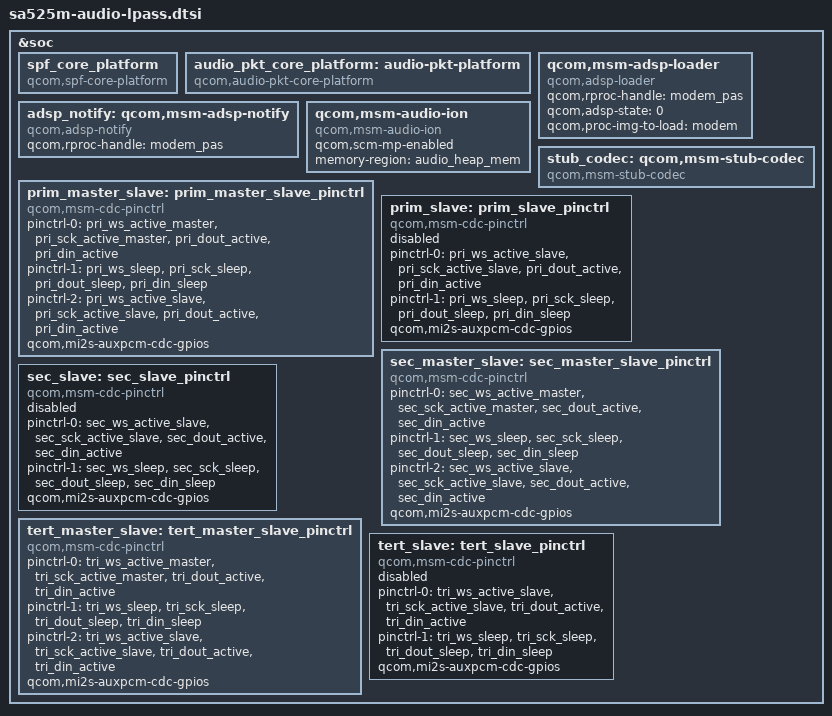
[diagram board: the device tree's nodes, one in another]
&soc {
	spf_core_platform: spf_core_platform {
		compatible = "qcom,spf-core-platform";
	};

	audio_pkt_core_platform: audio-pkt-platform {
		compatible = "qcom,audio-pkt-core-platform";
	};

	qcom,msm-adsp-loader {
		compatible = "qcom,adsp-loader";
		qcom,rproc-handle = <&modem_pas>;
		qcom,adsp-state = <0>;
		qcom,proc-img-to-load = "modem";
	};

	adsp_notify: qcom,msm-adsp-notify {
		status = "ok";
		compatible = "qcom,adsp-notify";
		qcom,rproc-handle = <&modem_pas>;
	};

	qcom,msm-audio-ion {
		compatible = "qcom,msm-audio-ion";
		qcom,scm-mp-enabled;
		memory-region = <&audio_heap_mem>;
	};

	stub_codec: qcom,msm-stub-codec {
		compatible = "qcom,msm-stub-codec";
	};

	prim_master_slave: prim_master_slave_pinctrl {
		compatible = "qcom,msm-cdc-pinctrl";
		pinctrl-names = "aud_active", "aud_sleep", "aud_alt_active";
		pinctrl-0 = <&pri_ws_active_master
				&pri_sck_active_master
				&pri_dout_active
				&pri_din_active>;
		pinctrl-1 = <&pri_ws_sleep
				&pri_sck_sleep
				&pri_dout_sleep
				&pri_din_sleep>;
		pinctrl-2 = <&pri_ws_active_slave
				&pri_sck_active_slave
				&pri_dout_active
				&pri_din_active>;
		qcom,mi2s-auxpcm-cdc-gpios;
	};

	prim_slave: prim_slave_pinctrl {
		status = "disabled";
		compatible = "qcom,msm-cdc-pinctrl";
		pinctrl-names = "aud_active", "aud_sleep";
		pinctrl-0 = <&pri_ws_active_slave
				&pri_sck_active_slave
				&pri_dout_active
				&pri_din_active>;
		pinctrl-1 = <&pri_ws_sleep
				&pri_sck_sleep
				&pri_dout_sleep
				&pri_din_sleep>;
		qcom,mi2s-auxpcm-cdc-gpios;
	};

	sec_master_slave: sec_master_slave_pinctrl {
		compatible = "qcom,msm-cdc-pinctrl";
		pinctrl-names = "aud_active", "aud_sleep", "aud_alt_active";
		pinctrl-0 = <&sec_ws_active_master
				&sec_sck_active_master
				&sec_dout_active
				&sec_din_active>;
		pinctrl-1 = <&sec_ws_sleep
				&sec_sck_sleep
				&sec_dout_sleep
				&sec_din_sleep>;
		pinctrl-2 = <&sec_ws_active_slave
				&sec_sck_active_slave
				&sec_dout_active
				&sec_din_active>;
		qcom,mi2s-auxpcm-cdc-gpios;
	};

	sec_slave: sec_slave_pinctrl {
		status = "disabled";
		compatible = "qcom,msm-cdc-pinctrl";
		pinctrl-names = "aud_active", "aud_sleep";
		pinctrl-0 = <&sec_ws_active_slave
				&sec_sck_active_slave
				&sec_dout_active
				&sec_din_active>;
		pinctrl-1 = <&sec_ws_sleep
				&sec_sck_sleep
				&sec_dout_sleep
				&sec_din_sleep>;
		qcom,mi2s-auxpcm-cdc-gpios;
	};

	tert_master_slave: tert_master_slave_pinctrl {
		compatible = "qcom,msm-cdc-pinctrl";
		pinctrl-names = "aud_active", "aud_sleep", "aud_alt_active";
		pinctrl-0 = <&tri_ws_active_master
				&tri_sck_active_master
				&tri_dout_active
				&tri_din_active>;
		pinctrl-1 = <&tri_ws_sleep
				&tri_sck_sleep
				&tri_dout_sleep
				&tri_din_sleep>;
		pinctrl-2 = <&tri_ws_active_slave
				&tri_sck_active_slave
				&tri_dout_active
				&tri_din_active>;
		qcom,mi2s-auxpcm-cdc-gpios;
	};

	tert_slave: tert_slave_pinctrl {
		status = "disabled";
		compatible = "qcom,msm-cdc-pinctrl";
		pinctrl-names = "aud_active", "aud_sleep";
		pinctrl-0 = <&tri_ws_active_slave
				&tri_sck_active_slave
				&tri_dout_active
				&tri_din_active>;
		pinctrl-1 = <&tri_ws_sleep
				&tri_sck_sleep
				&tri_dout_sleep
				&tri_din_sleep>;
		qcom,mi2s-auxpcm-cdc-gpios;
	};

};
